# CKGEN_CM1 register map
Vendor: Texas Instruments
Peripheral module from a debugger description file (folder omap4460).
Registers are 32-bit, access per field, reset 0x0 unless marked. A register's access mark holds for its fields unless they carry their own. Offsets are as the file gives them; lines under a group give offsets from that group; [hi:lo] are bit positions; {n}, {i} and the like mark numbered series; 'fields as' and 'values as' point back to an identical list; <NAME> marks a mode.

## CKGEN_CM1
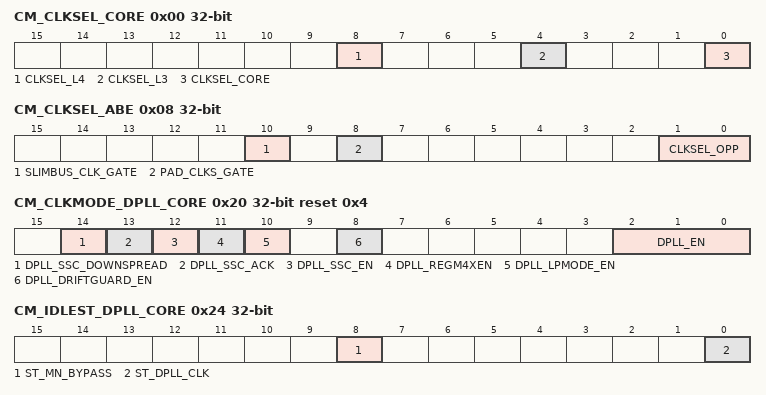
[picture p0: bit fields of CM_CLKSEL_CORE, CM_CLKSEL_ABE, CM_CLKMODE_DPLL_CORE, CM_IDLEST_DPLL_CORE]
0x00 CM_CLKSEL_CORE — CORE module clock selection.
  [8] CLKSEL_L4 rw — Selects L4 interconnect clock (L4_clk)
    0=L4_CLK is L3_CLK divided by 1; 1=L4_CLK is L3_CLK divided by 2, to be used for OPP100 and OPP50
  [4] CLKSEL_L3 rw — Selects L3 interconnect clock (L3_clk)
    0=L3_CLK is CORE_CLK divided by 1; 1=L3_CLK is CORE_CLK divided by 2, to be used for OPP100 and OPP50
  [0] CLKSEL_CORE rw — Selects CORE_CLK configuration
    0=CORE_CLK is CORE_X2_CLK divided by 1, to be used for OPP100 and OPP50; 1=CORE_CLK is CORE_X2_CLK divided by 2
0x08 CM_CLKSEL_ABE — ABE module clock selection.
  [10] SLIMBUS_CLK_GATE rw — Gating control for SLIMBUS_CLK clock tree in ABE. SLIMbus module always gets the ungated version.
    0=The clock is gated; 1=The clock is enabled
  [8] PAD_CLKS_GATE rw — Gating control for PAD_CLKS clock tree in ABE
    0=The clock is gated; 1=The clock is enabled
  [1:0] CLKSEL_OPP rw — Selects the OPP divider ABE domain
    0=ABE_CLK is divide by 1 of DPLL_ABE_X2_CLK, to be used for OPP100; 1=ABE_CLK is divide by 2 of DPLL_ABE_X2_CLK, to be used for OPP50; 2=ABE_CLK is divide by 4 of DPLL_ABE_X2_CLK
0x10 CM_DLL_CTRL reset 0x1 — Special register for DLL control
  [0] DLL_OVERRIDE rw — Control if DLL lock and code outputs are overriden or not
    0=Lock and code outputs are not overriden; 1=Lock output is overriden to 1 and code output is overriden with a value coming from control module
0x20 CM_CLKMODE_DPLL_CORE reset 0x4 — This register allows controlling the DPLL modes.
  [14] DPLL_SSC_DOWNSPREAD rw — Control if only low frequency spread is required
    0=When SSC is enabled, clock frequency is spread on both sides of the programmed frequency; 1=When SSC is enabled, clock frequency is spread only on the lower side of the programmed frequency
  [13] DPLL_SSC_ACK ro — Acknowledgement from the DPLL regarding start and stop of Spread Spectrum Clocking feature
    0=DPLL_SSC_ACK_0_r (SSC has been turned off on PLL o/ps); 1=DPLL_SSC_ACK_1_r (SSC has been turned on on PLL o/ps)
  [12] DPLL_SSC_EN rw — Enable or disable Spread Spectrum Clocking
    0=SSC disabled; 1=SSC enabled
  [11] DPLL_REGM4XEN ro — Enable the REGM4XEN mode of the DPLL. Please check the DPLL documentation to check when this mode can be enabled.
    0=DPLL_REGM4XEN_0_r (REGM4XEN mode of the DPLL is disabled)
  [10] DPLL_LPMODE_EN rw — Set the DPLL in low-power mode. Check the DPLL documentation to see when this can be enabled.
    0=Low-power mode of the DPLL is disabled; 1=Low-power mode of the DPLL is enabled
  [8] DPLL_DRIFTGUARD_EN rw — This bit allows to enable or disable the automatic recalibration feature of the DPLL. The DPLL will automatically start a recalibration process upon assertion of the DPLL's RECAL flag if this bit is set.
    0=DRIFTGUARD feature is disabled; 1=DRIFTGUARD feature is enabled
  [2:0] DPLL_EN rw — DPLL control. Upon Warm Reset, the PRCM DPLL control state machine updates this register to reflect MN bypass mode.
    4=Put the DPLL in MN bypass mode. The DPLL_MULT register bits are reset to 0 automatically by putting the DPLL in this mode.; 5=Put the DPLL in Idle bypass low-power mode; 6=Put the DPLL in Idle bypass fast-relock mode; 7=Enables the DPLL in lock mode
0x24 CM_IDLEST_DPLL_CORE ro — This register allows monitoring DPLL activity. This register is read only and automatically updated. [warm reset insensitive]
  [8] ST_MN_BYPASS — DPLL MN_BYPASS status
    1=ST_MN_BYPASS_1_r (DPLL is in MN_Bypass); 0=ST_MN_BYPASS_0_r (DPLL is not in MN_Bypass)
  [0] ST_DPLL_CLK — DPLL lock status
    1=ST_DPLL_CLK_1_r (DPLL is LOCKED); 0=ST_DPLL_CLK_0_r (DPLL is either in bypass mode or in stop mode.)
0x28 CM_AUTOIDLE_DPLL_CORE — This register provides automatic control over the DPLL activity.
  [2:0] AUTO_DPLL_MODE rw — DPLL automatic control.
    0=DPLL auto control disabled; 1=The DPLL is automatically put in low-power stop mode when its DPLL generated clocks are not required anymore. It is also restarted automatically.; 2=The DPLL is automatically put in fast-relock stop mode when its DPLL generated clocks are not required anymore. It is also restarted automatically.; 5=The DPLL is automatically put in idle bypass low-power mode when its DPLL generated clocks are not required anymore. It is also restarted automatically.; 6=The DPLL is automatically put in idle bypass fast-relock mode when its DPLL generated clocks are not required anymore. It is also restarted automatically.
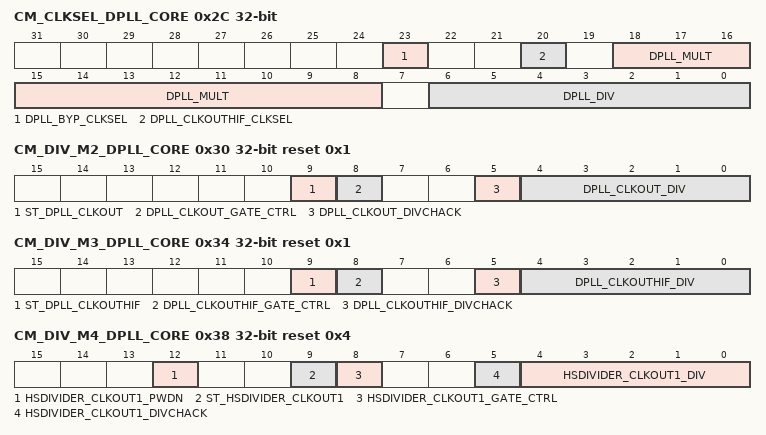
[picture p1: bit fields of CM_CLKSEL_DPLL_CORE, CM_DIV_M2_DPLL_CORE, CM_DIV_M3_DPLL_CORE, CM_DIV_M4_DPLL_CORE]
0x2C CM_CLKSEL_DPLL_CORE — This register provides controls over the DPLL.
  [23] DPLL_BYP_CLKSEL rw — Allows control of the BYPASS clock of the PLL and the associated HSDIVIDER. Same as ULOWCLKEN on DPLL. In DPLL locked mode, 0 - No impact 1 - No impact In DPLL bypass mode, 0 - CLKINP is selected as the BYPASS clock for CLKOUT/CLKOUTX2 1 - CLKINPULOW is selected as the BYPASS clock for CLKOUT/CLKOUTX2
  [20] DPLL_CLKOUTHIF_CLKSEL rw — Selects the source of the DPLL CLKOUTHIF clock. Same as CLKINPHIFSEL pin on the DPLL
    0=CLKOUTHIF is generated from the DPLL oscillator (DCO); 1=CLKOUTHIF is generated from CLKINPHIF
  [18:8] DPLL_MULT rw — DPLL multiplier factor (2 to 2047). This register is automatically cleared to 0 when the DPLL_EN field in the *CLKMODE_DPLL* register is set to select MN bypass mode. (equal to input M of DPLL; M=2 to 2047 = DPLL multiplies by M).
  [6:0] DPLL_DIV rw — DPLL divider factor (0 to 127) (equal to input N of DPLL; actual division factor is N+1).
0x30 CM_DIV_M2_DPLL_CORE reset 0x1 — This register provides controls over the M2 divider of the DPLL.
  [9] ST_DPLL_CLKOUT ro — DPLL CLKOUT status
    0=ST_DPLL_CLKOUT_0_r (The clock output is gated); 1=ST_DPLL_CLKOUT_1_r (The clock output is enabled)
  [8] DPLL_CLKOUT_GATE_CTRL rw — Control gating of DPLL CLKOUT
    0=Automatically gate this clock when there is no dependency for it; 1=Force this clock to stay enabled even if there is no request
  [5] DPLL_CLKOUT_DIVCHACK ro — Toggle on this status bit after changing DPLL_CLKOUT_DIV indicates that the change in divider value has taken effect
  [4:0] DPLL_CLKOUT_DIV rw — DPLL post-divider factor, M2, for internal clock generation (1 to 31); Divide value from 1 to 31.
    1=1, to be used for OPP100; 2=2, to be used for OPP50
0x34 CM_DIV_M3_DPLL_CORE reset 0x1 — This register provides controls over the M3 divider of the DPLL.
  [9] ST_DPLL_CLKOUTHIF ro — DPLL CLKOUTHIF status
    0=ST_DPLL_CLKOUTHIF_0_r (The clock output is gated); 1=ST_DPLL_CLKOUTHIF_1_r (The clock output is enabled)
  [8] DPLL_CLKOUTHIF_GATE_CTRL rw — Control gating of DPLL CLKOUTHIF
    0=Gate unconditionally this clock and stop requesting it; 1=Request this clock and un-gate it when available
  [5] DPLL_CLKOUTHIF_DIVCHACK ro — Toggle on this status bit after changing DPLL_CLKOUTHIF_DIV indicates that the change in divider value has taken effect
  [4:0] DPLL_CLKOUTHIF_DIV rw — DPLL post-divider factor, M3, for internal clock generation (1 to 31). Divide value from 1 to 31
    5=5, to be used for OPP100; 8=8, to be used for OPP50
0x38 CM_DIV_M4_DPLL_CORE reset 0x4 — This register provides controls over the CLKOUT1 o/p of the HSDIVIDER.
  [12] HSDIVIDER_CLKOUT1_PWDN rw — Direct power down control for HSDIVIDER M4 divider and CLKOUT1 output. Power down should be enabled only when clock is first gated.
    0=Divider is powered up; 1=Divider is powered down
  [9] ST_HSDIVIDER_CLKOUT1 ro — HSDIVIDER CLKOUT1 status
    0=ST_HSDIVIDER_CLKOUT1_0_r (The clock output is gated); 1=ST_HSDIVIDER_CLKOUT1_1_r (The clock output is enabled)
  [8] HSDIVIDER_CLKOUT1_GATE_CTRL rw — Control gating of HSDIVIDER CLKOUT1
    values as CM_DIV_M2_DPLL_CORE.DPLL_CLKOUT_GATE_CTRL
  [5] HSDIVIDER_CLKOUT1_DIVCHACK ro — Toggle on this status bit after changing HSDIVIDER_CLKOUT1_DIV indicates that the change in divider value has taken effect
  [4:0] HSDIVIDER_CLKOUT1_DIV rw — DPLL M4 post-divider factor (1 to 31).
    8=8, to be used for OPP100 and OPP50
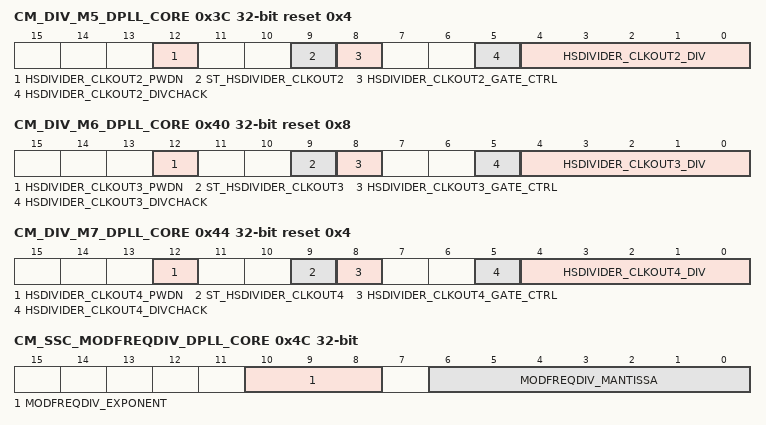
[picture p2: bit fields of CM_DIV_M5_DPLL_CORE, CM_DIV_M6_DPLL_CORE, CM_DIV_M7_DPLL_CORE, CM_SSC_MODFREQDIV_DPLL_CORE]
0x3C CM_DIV_M5_DPLL_CORE reset 0x4 — This register provides controls over the CLKOUT2 o/p of the HSDIVIDER.
  [12] HSDIVIDER_CLKOUT2_PWDN rw — Direct power down control for HSDIVIDER M5 divider and CLKOUT2 output. Power down should be enabled only when clock is first gated.
    0=Divider is powered up; 1=Divider is powered down
  [9] ST_HSDIVIDER_CLKOUT2 ro — HSDIVIDER CLKOUT2 status
    0=ST_HSDIVIDER_CLKOUT2_0_r (The clock output is gated); 1=ST_HSDIVIDER_CLKOUT2_1_r (The clock output is enabled)
  [8] HSDIVIDER_CLKOUT2_GATE_CTRL rw — Control gating of HSDIVIDER CLKOUT2
    values as CM_DIV_M2_DPLL_CORE.DPLL_CLKOUT_GATE_CTRL
  [5] HSDIVIDER_CLKOUT2_DIVCHACK ro — Toggle on this status bit after changing HSDIVIDER_CLKOUT2_DIV indicates that the change in divider value has taken effect
  [4:0] HSDIVIDER_CLKOUT2_DIV rw — DPLL M5 post-divider factor (1 to 31)
    4=4, to be used for OPP100; 8=8, to be used for OPP50
0x40 CM_DIV_M6_DPLL_CORE reset 0x8 — This register provides controls over the CLKOUT3 o/p of the HSDIVIDER.
  [12] HSDIVIDER_CLKOUT3_PWDN rw — Direct power down control for HSDIVIDER M6 divider and CLKOUT3 output. Power down should be enabled only when clock is first gated.
    0=Divider is powered up; 1=Divider is powered down
  [9] ST_HSDIVIDER_CLKOUT3 ro — HSDIVIDER CLKOUT3 status
    0=ST_HSDIVIDER_CLKOUT3_0_r (The clock output is gated); 1=ST_HSDIVIDER_CLKOUT3_1_r (The clock output is enabled)
  [8] HSDIVIDER_CLKOUT3_GATE_CTRL rw — Control gating of HSDIVIDER CLKOUT3
    values as CM_DIV_M2_DPLL_CORE.DPLL_CLKOUT_GATE_CTRL
  [5] HSDIVIDER_CLKOUT3_DIVCHACK ro — Toggle on this status bit after changing HSDIVIDER_CLKOUT3_DIV indicates that the change in divider value has taken effect
  [4:0] HSDIVIDER_CLKOUT3_DIV rw — DPLL M6 post-divider factor (1 to 31)
    6=6, to be used for OPP100; 8=8, to be used for OPP50
0x44 CM_DIV_M7_DPLL_CORE reset 0x4 — This register provides controls over the CLKOUT4 o/p of the HSDIVIDER.
  [12] HSDIVIDER_CLKOUT4_PWDN rw — Direct power down control for HSDIVIDER M7 divider and CLKOUT4 output. Power down should be enabled only when clock is first gated.
    0=Divider is powered up; 1=Divider is powered down
  [9] ST_HSDIVIDER_CLKOUT4 ro — HSDIVIDER CLKOUT4 status
    0=ST_HSDIVIDER_CLKOUT4_0_r (The clock output is gated); 1=ST_HSDIVIDER_CLKOUT4_1_r (The clock output is enabled)
  [8] HSDIVIDER_CLKOUT4_GATE_CTRL rw — Control gating of HSDIVIDER CLKOUT4
    values as CM_DIV_M2_DPLL_CORE.DPLL_CLKOUT_GATE_CTRL
  [5] HSDIVIDER_CLKOUT4_DIVCHACK ro — Toggle on this status bit after changing HSDIVIDER_CLKOUT4_DIV indicates that the change in divider value has taken effect
  [4:0] HSDIVIDER_CLKOUT4_DIV rw — DPLL M7 post-divider factor (1 to 31)
    6=6, to be used for OPP100 for 266.7-MHz clock output; 8=8, to be used for OPP100 for 200-MHz clock output; 12=12, to be used for OPP50 for 133.3-MHz clock output; 16=16, to be used for OPP50 for 100-MHz clock output
0x48 CM_SSC_DELTAMSTEP_DPLL_CORE — Control the DeltaMStep parameter for Spread Spectrum Clocking. [warm reset insensitive]
  [19:0] DELTAMSTEP rw — DeltaMStep is split into fractional and integer part. For Triangular Spread Spectrum: [19:18] for integer part, [17:0] for fractional part For Square Wave Spread Spectrum [19:14] for integer part, [13:0] for fractional part
0x4C CM_SSC_MODFREQDIV_DPLL_CORE — Control the Modulation Frequency (Fm) for Spread Spectrum. [warm reset insensitive]
  [10:8] MODFREQDIV_EXPONENT rw — Set the Exponent component of MODFREQDIV factor
  [6:0] MODFREQDIV_MANTISSA rw — Set the Mantissa component of MODFREQDIV factor
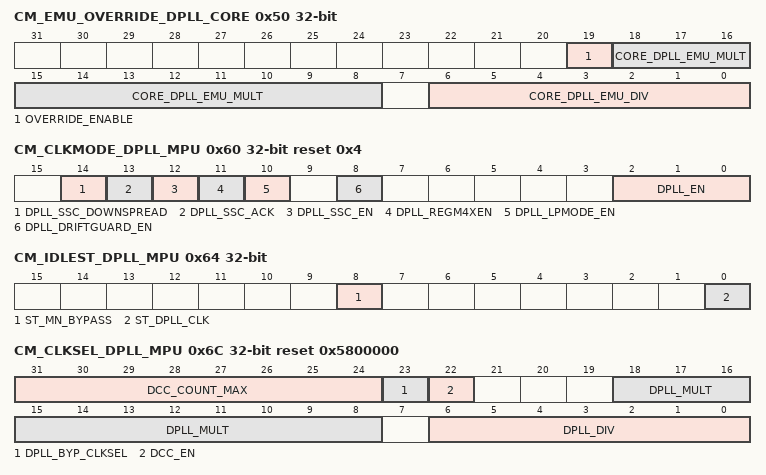
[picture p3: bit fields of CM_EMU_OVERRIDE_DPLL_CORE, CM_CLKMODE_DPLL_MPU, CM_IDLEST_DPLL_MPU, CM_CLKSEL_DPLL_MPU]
0x50 CM_EMU_OVERRIDE_DPLL_CORE — This register provides emulation override controls over the CORE DPLL.
  [19] OVERRIDE_ENABLE rw — This bit allows to enable or disable the emulation override controls
    0=The emulation override controls are disabled; 1=The emulation override controls are enabled
  [18:8] CORE_DPLL_EMU_MULT rw — DPLL multiplier factor (2 to 2047). (equal to input M of DPLL; M=2 to 2047 = DPLL multiplies by M)
  [6:0] CORE_DPLL_EMU_DIV rw — CORE DPLL override divider factor (0 to 127) (equal to input N of DPLL; actual division factor is N+1).
0x60 CM_CLKMODE_DPLL_MPU reset 0x4 — This register allows controlling the DPLL modes.
  [14] DPLL_SSC_DOWNSPREAD rw — Control if only low frequency spread is required
    values as CM_CLKMODE_DPLL_CORE.DPLL_SSC_DOWNSPREAD
  [13] DPLL_SSC_ACK ro — Acknowledgement from the DPLL regarding start and stop of Spread Spectrum Clocking feature
    values as CM_CLKMODE_DPLL_CORE.DPLL_SSC_ACK
  [12] DPLL_SSC_EN rw — Enable or disable Spread Spectrum Clocking
    0=SSC disabled; 1=SSC enabled
  [11] DPLL_REGM4XEN ro — Enable the REGM4XEN mode of the DPLL. Please check the DPLL documentation to check when this mode can be enabled.
    0=DPLL_REGM4XEN_0_r (REGM4XEN mode of the DPLL is disabled)
  [10] DPLL_LPMODE_EN rw — Set the DPLL in low-power mode. Check the DPLL documentation to see when this can be enabled.
    values as CM_CLKMODE_DPLL_CORE.DPLL_LPMODE_EN
  [8] DPLL_DRIFTGUARD_EN rw — This bit allows to enable or disable the automatic recalibration feature of the DPLL. The DPLL will automatically start a recalibration process upon assertion of the DPLL's RECAL flag if this bit is set.
    values as CM_CLKMODE_DPLL_CORE.DPLL_DRIFTGUARD_EN
  [2:0] DPLL_EN rw — DPLL control. Upon Warm Reset, the PRCM DPLL control state machine updates this register to reflect MN bypass mode.
    4=Put the DPLL in MN bypass mode. The DPLL_MULT register bits are reset to 0 automatically by putting the DPLL in this mode.; 5=Put the DPLL in idle bypass low-power mode; 6=Put the DPLL in idle bypass fast-relock mode; 7=Enables the DPLL in lock mode
0x64 CM_IDLEST_DPLL_MPU ro — This register allows monitoring DPLL activity. This register is read only and automatically updated. [warm reset insensitive]
  fields as CM_IDLEST_DPLL_CORE
0x68 CM_AUTOIDLE_DPLL_MPU — This register provides automatic control over the DPLL activity.
  [2:0] AUTO_DPLL_MODE rw — DPLL automatic control;
    values as CM_AUTOIDLE_DPLL_CORE.AUTO_DPLL_MODE
0x6C CM_CLKSEL_DPLL_MPU access not given reset 0x5800000 — This register provides controls over the DPLL.
  [31:24] DCC_COUNT_MAX rw — The value 'NbCycles' set in this field determines the duration of the clock ramp step during which the output frequency is Fdpll/(2*M2). The duration is computed as 32 x NbCycles of L4 clock cycles (100 MHz). Duration should be 2.5 µs to allow enough time for DCC to lock. This bit field is relevant only when DCC_EN = 1.
  [23] DPLL_BYP_CLKSEL — Only CLKINPULOW bypass clock supported for this PLL (access R Returns 1s)
  [22] DCC_EN rw — Enable or disable duty cycle correction. Must be enabled only for frequency 1 GHz.When enabled, the CLKOUTHIF output of the DPLL is used after duty cycle correction instead of CLKOUT. The M3 divider is hard-wired to 1 so the lock frequency Fdpll is directly provided to MPU. .
    0=DCC disabled; 1=DCC enabled
  [18:8] DPLL_MULT rw — DPLL multiplier factor (2 to 2047). This register is automatically cleared to 0 when the DPLL_EN field in the *CLKMODE_DPLL* register is set to select MN bypass mode. (equal to input M of DPLL; M=2 to 2047 = DPLL multiplies by M).
  [6:0] DPLL_DIV rw — DPLL divider factor (0 to 127) (equal to input N of DPLL; actual division factor is N+1).
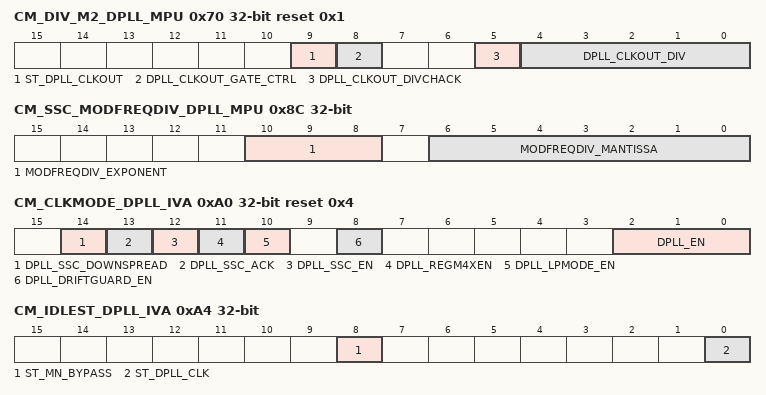
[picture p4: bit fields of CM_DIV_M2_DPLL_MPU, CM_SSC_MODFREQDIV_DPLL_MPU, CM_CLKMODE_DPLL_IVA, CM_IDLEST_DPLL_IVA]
0x70 CM_DIV_M2_DPLL_MPU reset 0x1 — This register provides controls over the M2 divider of the DPLL.
  [9] ST_DPLL_CLKOUT ro — DPLL CLKOUT status
    values as CM_DIV_M2_DPLL_CORE.ST_DPLL_CLKOUT
  [8] DPLL_CLKOUT_GATE_CTRL rw — Control gating of DPLL CLKOUT
    values as CM_DIV_M2_DPLL_CORE.DPLL_CLKOUT_GATE_CTRL
  [5] DPLL_CLKOUT_DIVCHACK ro — Toggle on this status bit after changing DPLL_CLKOUT_DIV indicates that the change in divider value has taken effect
  [4:0] DPLL_CLKOUT_DIV rw — DPLL post-divider factor, M2, for internal clock generation (1 to 31);Divide value from 1 to 31
    1=1, to be used for OPP100, OPP_TURBO, OPP_NITRO, and OPP_NITROSB; 2=2, to be used for OPP50
0x88 CM_SSC_DELTAMSTEP_DPLL_MPU — Control the DeltaMStep parameter for Spread Spectrum Clocking. [warm reset insensitive]
  fields as CM_SSC_DELTAMSTEP_DPLL_CORE
0x8C CM_SSC_MODFREQDIV_DPLL_MPU — Control the Modulation Frequency (Fm) for Spread Spectrum. [warm reset insensitive]
  fields as CM_SSC_MODFREQDIV_DPLL_CORE
0x9C CM_BYPCLK_DPLL_MPU — Control MPU PLL BYPASS clock. [warm reset insensitive]
  [1:0] CLKSEL rw — Select the DPLL MPU bypass clock
    0=DPLL_MPU bypass clock is CORE_X2_CLK divided by 1, to be used for OPP100 and OPP50; 1=DPLL_MPU bypass clock is CORE_X2_CLK divided by 2; 2=DPLL_MPU bypass clock is CORE_X2_CLK divided by 4; 3=DPLL_MPU bypass clock is CORE_X2_CLK divided by 8
0xA0 CM_CLKMODE_DPLL_IVA reset 0x4 — This register allows controlling the DPLL modes.
  [14] DPLL_SSC_DOWNSPREAD rw — Control if only low frequency spread is required
    values as CM_CLKMODE_DPLL_CORE.DPLL_SSC_DOWNSPREAD
  [13] DPLL_SSC_ACK ro — Acknowledgement from the DPLL regarding start and stop of Spread Spectrum Clocking feature
    values as CM_CLKMODE_DPLL_CORE.DPLL_SSC_ACK
  [12] DPLL_SSC_EN rw — Enable or disable Spread Spectrum Clocking
    0=SSC disabled; 1=SSC enabled
  [11] DPLL_REGM4XEN ro — Enable the REGM4XEN mode of the DPLL. Please check the DPLL documentation to check when this mode can be enabled.
    0=DPLL_REGM4XEN_0_r (REGM4XEN mode of the DPLL is disabled)
  [10] DPLL_LPMODE_EN rw — Set the DPLL in low-power mode. Check the DPLL documentation to see when this can be enabled.
    values as CM_CLKMODE_DPLL_CORE.DPLL_LPMODE_EN
  [8] DPLL_DRIFTGUARD_EN rw — This bit allows to enable or disable the automatic recalibration feature of the DPLL. The DPLL will automatically start a recalibration process upon assertion of the DPLL's RECAL flag if this bit is set.
    values as CM_CLKMODE_DPLL_CORE.DPLL_DRIFTGUARD_EN
  [2:0] DPLL_EN rw — DPLL control. Upon Warm Reset, the PRCM DPLL control state machine updates this register to reflect MN bypass mode.
    4=Put the DPLL in MN bypass mode. The DPLL_MULT register bits are reset to 0 automatically by putting the DPLL in this mode.; 5=Put the DPLL in idle bypass low-power mode; 7=Enables the DPLL in lock mode
0xA4 CM_IDLEST_DPLL_IVA ro — This register allows monitoring DPLL activity. This register is read only and automatically updated. [warm reset insensitive]
  fields as CM_IDLEST_DPLL_CORE
0xA8 CM_AUTOIDLE_DPLL_IVA — This register provides automatic control over the DPLL activity.
  [2:0] AUTO_DPLL_MODE rw — DPLL automatic control;
    0=DPLL auto control disabled; 1=The DPLL is automatically put in low-power stop mode when its DPLL generated clocks are not required anymore. It is also restarted automatically.; 2=The DPLL is automatically put in fast-relock stop mode when its DPLL generated clocks are not required anymore. It is also restarted automatically.; 5=The DPLL is automatically put in idle bypass low-power mode when its DPLL generated clocks are not required anymore. It is also restarted automatically.
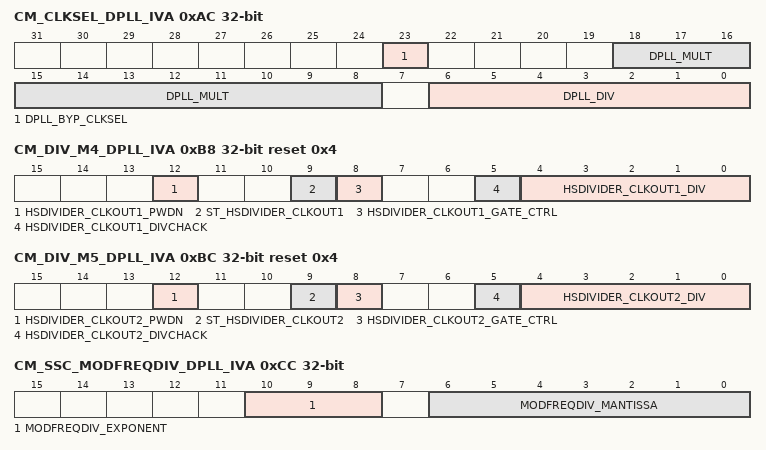
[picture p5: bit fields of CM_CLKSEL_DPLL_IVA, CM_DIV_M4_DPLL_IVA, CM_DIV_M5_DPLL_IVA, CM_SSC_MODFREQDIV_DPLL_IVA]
0xAC CM_CLKSEL_DPLL_IVA — This register provides controls over the DPLL.
  [23] DPLL_BYP_CLKSEL rw — Allows control of the BYPASS clock of the PLL and the associated HSDIVIDER. Same as ULOWCLKEN on DPLL. In DPLL locked mode, 0 - No impact 1 - No impact In DPLL bypass mode, 0 - CLKINP is selected as the BYPASS clock for CLKOUT/CLKOUTX2 1 - CLKINPULOW is selected as the BYPASS clock for CLKOUT/CLKOUTX2
  [18:8] DPLL_MULT rw — DPLL multiplier factor (2 to 2047). This register is automatically cleared to 0 when the DPLL_EN field in the *CLKMODE_DPLL* register is set to select MN bypass mode. (equal to input M of DPLL; M=2 to 2047 = DPLL multiplies by M).
  [6:0] DPLL_DIV rw — DPLL divider factor (0 to 127) (equal to input N of DPLL; actual division factor is N+1).
0xB8 CM_DIV_M4_DPLL_IVA reset 0x4 — This register provides controls over the CLKOUT1 o/p of the HSDIVIDER.
  [12] HSDIVIDER_CLKOUT1_PWDN rw — Direct power down control for HSDIVIDER M4 divider and CLKOUT1 output. Power down should be enabled only when clock is first gated.
    0=Divider is powered up; 1=Divider is powered down
  [9] ST_HSDIVIDER_CLKOUT1 ro — HSDIVIDER CLKOUT1 status
    values as CM_DIV_M4_DPLL_CORE.ST_HSDIVIDER_CLKOUT1
  [8] HSDIVIDER_CLKOUT1_GATE_CTRL rw — Control gating of HSDIVIDER CLKOUT1
    values as CM_DIV_M2_DPLL_CORE.DPLL_CLKOUT_GATE_CTRL
  [5] HSDIVIDER_CLKOUT1_DIVCHACK ro — Toggle on this status bit after changing HSDIVIDER_CLKOUT1_DIV indicates that the change in divider value has taken effect
  [4:0] HSDIVIDER_CLKOUT1_DIV rw — DPLL M4 post-divider factor (1 to 31)
    2=2, to be used for OPP_TURBO and OPP_NITRO; 4=4, to be used for OPP100; 8=8, to be used for OPP50
0xBC CM_DIV_M5_DPLL_IVA reset 0x4 — This register provides controls over the CLKOUT2 o/p of the HSDIVIDER.
  [12] HSDIVIDER_CLKOUT2_PWDN rw — Direct power down control for HSDIVIDER M5 divider and CLKOUT2 output. Power down should be enabled only when clock is first gated.
    0=Divider is powered up; 1=Divider is powered down
  [9] ST_HSDIVIDER_CLKOUT2 ro — HSDIVIDER CLKOUT2 status
    values as CM_DIV_M5_DPLL_CORE.ST_HSDIVIDER_CLKOUT2
  [8] HSDIVIDER_CLKOUT2_GATE_CTRL rw — Control gating of HSDIVIDER CLKOUT2
    values as CM_DIV_M2_DPLL_CORE.DPLL_CLKOUT_GATE_CTRL
  [5] HSDIVIDER_CLKOUT2_DIVCHACK ro — Toggle on this status bit after changing HSDIVIDER_CLKOUT2_DIV indicates that the change in divider value has taken effect.
  [4:0] HSDIVIDER_CLKOUT2_DIV rw — DPLL M5 post-divider factor (1 to 31)
    2=2, to be used for OPP_NITRO; 3=3, to be used for OPP_TURBO; 7=7, to be used for OPP100; 14=14, to be used for OPP50
0xC8 CM_SSC_DELTAMSTEP_DPLL_IVA — Control the DeltaMStep parameter for Spread Spectrum Clocking. [warm reset insensitive]
  fields as CM_SSC_DELTAMSTEP_DPLL_CORE
0xCC CM_SSC_MODFREQDIV_DPLL_IVA — Control the Modulation Frequency (Fm) for Spread Spectrum. [warm reset insensitive]
  fields as CM_SSC_MODFREQDIV_DPLL_CORE
0xDC CM_BYPCLK_DPLL_IVA — Control IVA PLL BYPASS clock. [warm reset insensitive]
  [1:0] CLKSEL rw — Select the DPLL IVA bypass clock
    0=DPLL_IVA bypass clock is CORE_X2_CLK divided by 1, to be used for OPP100 and OPP50; 1=DPLL_IVA bypass clock is CORE_X2_CLK divided by 2; 2=DPLL_IVA bypass clock is CORE_X2_CLK divided by 4; 3=DPLL_IVA bypass clock is CORE_X2_CLK divided by 8
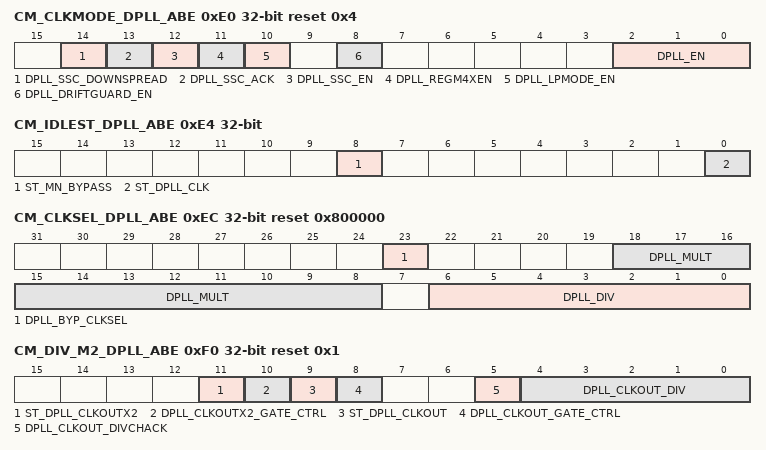
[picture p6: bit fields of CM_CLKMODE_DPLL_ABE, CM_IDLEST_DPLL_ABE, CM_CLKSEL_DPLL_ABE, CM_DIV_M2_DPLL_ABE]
0xE0 CM_CLKMODE_DPLL_ABE reset 0x4 — This register allows controlling the DPLL modes.
  [14] DPLL_SSC_DOWNSPREAD rw — Control if only low frequency spread is required
    values as CM_CLKMODE_DPLL_CORE.DPLL_SSC_DOWNSPREAD
  [13] DPLL_SSC_ACK ro — Acknowledgement from the DPLL regarding start and stop of Spread Spectrum Clocking feature
    values as CM_CLKMODE_DPLL_CORE.DPLL_SSC_ACK
  [12] DPLL_SSC_EN rw — Enable or disable Spread Spectrum Clocking
    0=SSC disabled; 1=SSC enabled
  [11] DPLL_REGM4XEN rw — Enable the REGM4XEN mode of the DPLL. Please check the DPLL documentation to check when this mode can be enabled.
    0=DPLL_REGM4XEN_0_r (REGM4XEN mode of the DPLL is disabled)
  [10] DPLL_LPMODE_EN rw — Set the DPLL in low-power mode. Check the DPLL documentation to see when this can be enabled.
    values as CM_CLKMODE_DPLL_CORE.DPLL_LPMODE_EN
  [8] DPLL_DRIFTGUARD_EN rw — This bit allows to enable or disable the automatic recalibration feature of the DPLL. The DPLL will automatically start a recalibration process upon assertion of the DPLL's RECAL flag if this bit is set.
    values as CM_CLKMODE_DPLL_CORE.DPLL_DRIFTGUARD_EN
  [2:0] DPLL_EN rw — DPLL control. Upon Warm Reset, the PRCM DPLL control state machine updates this register to reflect MN bypass mode.
    values as CM_CLKMODE_DPLL_MPU.DPLL_EN
0xE4 CM_IDLEST_DPLL_ABE ro — This register allows monitoring DPLL activity. This register is read only and automatically updated. [warm reset insensitive]
  fields as CM_IDLEST_DPLL_CORE
0xE8 CM_AUTOIDLE_DPLL_ABE — This register provides automatic control over the DPLL activity.
  fields as CM_AUTOIDLE_DPLL_MPU
0xEC CM_CLKSEL_DPLL_ABE access not given reset 0x800000 — This register provides controls over the DPLL.
  [23] DPLL_BYP_CLKSEL — Only CLKINPULOW bypass clock supported for this PLL (access R Rreturns1s)
  [18:8] DPLL_MULT rw — DPLL multiplier factor (2 to 2047). This register is automatically cleared to 0 when the DPLL_EN field in the *CLKMODE_DPLL* register is set to select MN bypass mode. (equal to input M of DPLL; M=2 to 2047 = DPLL multiplies by M).
  [6:0] DPLL_DIV rw — DPLL divider factor (0 to 127) (equal to input N of DPLL; actual division factor is N+1).
0xF0 CM_DIV_M2_DPLL_ABE reset 0x1 — This register provides controls over the M2 divider of the DPLL.
  [11] ST_DPLL_CLKOUTX2 ro — DPLL CLKOUTX2 status
    0=ST_DPLL_CLKOUTX2_0_r (The clock output is gated); 1=ST_DPLL_CLKOUTX2_1_r (The clock output is enabled)
  [10] DPLL_CLKOUTX2_GATE_CTRL rw — Control gating of DPLL CLKOUTX2
    values as CM_DIV_M2_DPLL_CORE.DPLL_CLKOUT_GATE_CTRL
  [9] ST_DPLL_CLKOUT ro — DPLL CLKOUT status
    values as CM_DIV_M2_DPLL_CORE.ST_DPLL_CLKOUT
  [8] DPLL_CLKOUT_GATE_CTRL rw — Control gating of DPLL CLKOUT
    values as CM_DIV_M2_DPLL_CORE.DPLL_CLKOUT_GATE_CTRL
  [5] DPLL_CLKOUT_DIVCHACK ro — Toggle on this status bit after changing DPLL_CLKOUT_DIV indicates that the change in divider value has taken effect.
  [4:0] DPLL_CLKOUT_DIV rw — DPLL post-divider factor, M2, for internal clock generation (1 to 31). Divide value from 1 to 31
    1=1, to be used for OPP100 and OPP50
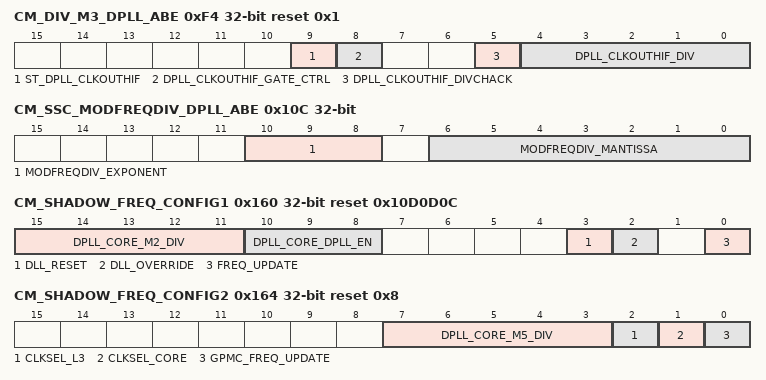
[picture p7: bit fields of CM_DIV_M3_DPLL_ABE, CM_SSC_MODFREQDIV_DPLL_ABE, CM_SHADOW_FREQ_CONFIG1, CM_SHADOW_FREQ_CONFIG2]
0xF4 CM_DIV_M3_DPLL_ABE reset 0x1 — This register provides controls over the M3 divider of the DPLL.
  [9] ST_DPLL_CLKOUTHIF ro — DPLL CLKOUTHIF status
    values as CM_DIV_M3_DPLL_CORE.ST_DPLL_CLKOUTHIF
  [8] DPLL_CLKOUTHIF_GATE_CTRL rw — Control gating of DPLL CLKOUTHIF
    values as CM_DIV_M2_DPLL_CORE.DPLL_CLKOUT_GATE_CTRL
  [5] DPLL_CLKOUTHIF_DIVCHACK ro — Toggle on this status bit after changing DPLL_CLKOUTHIF_DIV indicates that the change in divider value has taken effect.
  [4:0] DPLL_CLKOUTHIF_DIV rw — DPLL post-divider factor, M3, for internal clock generation (1 to 31). Divide value from 1 to 31
    1=1, to be used for OPP100 and OPP50
0x108 CM_SSC_DELTAMSTEP_DPLL_ABE — Control the DeltaMStep parameter for Spread Spectrum Clocking. [warm reset insensitive]
  fields as CM_SSC_DELTAMSTEP_DPLL_CORE
0x10C CM_SSC_MODFREQDIV_DPLL_ABE — Control the Modulation Frequency (Fm) for Spread Spectrum. [warm reset insensitive]
  fields as CM_SSC_MODFREQDIV_DPLL_CORE
0x160 CM_SHADOW_FREQ_CONFIG1 access not given reset 0x10D0D0C — Shadow register to program new DPLL configuration affecting EMIF and GPMC (L3 clock) functional frequency during DVFS. The PRCM h/w automatically applies the new configuration after EMIF/GPMC have been put in idle state.
  [15:11] DPLL_CORE_M2_DIV rw — Shadow register forCM_DIV_M2_DPLL_CORE.DPLL_CLKOUT_DIV. The main register is automatically loaded with the shadow register value after EMIF IDLE if the FREQ_UPDATE field is set to 1. Divide value from 1 to 31.
  [10:8] DPLL_CORE_DPLL_EN rw — Shadow register forCM_CLKMODE_DPLL_CORE.DPLL_EN. The main register is automatically loaded with the shadow register value after EMIF IDLE if the FREQ_UPDATE field is set to 1.
    values as CM_CLKMODE_DPLL_MPU.DPLL_EN
  [3] DLL_RESET rw — Specify if DLL should be reset or not during the frequency change hardware sequence.
    0=DLL is not reset during the frequency change hardware sequence; 1=DLL is reset automatically during the frequency change hardware sequence
  [2] DLL_OVERRIDE rw — Shadow register forCM_DLL_CTRL.DLL_OVERRIDE.The main register is automatically loaded with the shadow register value after EMIF IDLE if the FREQ_UPDATE field is set to 1.
    values as CM_DLL_CTRL.DLL_OVERRIDE
  [0] FREQ_UPDATE — Writing 1 indicates that a new configuration is available. It is automatically cleared by h/w after the configuration has been applied. (access RW WSpecial)
0x164 CM_SHADOW_FREQ_CONFIG2 reset 0x8 — Shadow register to program new DPLL configuration affecting GPMC (L3 clock) functional frequency during DVFS. The PRCM h/w automatically applies the new configuration after EMIF/GPMC have been put in idle state.
  [7:3] DPLL_CORE_M5_DIV rw — Shadow register forCM_DIV_M5_DPLL_CORE.HSDIVIDER_CLKOUT2_DIV. The main register is automatically loaded with the shadow register value after GPMC IDLE if the CM_SHADOW_FREQ_CONFIG1.FREQ_UPDATE field is set to 1 and GPMC_FREQ_UPDATE is set to 1. Divide value from 1 to 31.
  [2] CLKSEL_L3 rw — Shadow register forCM_CLKSEL_CORE.CLKSEL_L3. The main register is automatically loaded with the shadow register value after GPMC IDLE if the CM_SHADOW_FREQ_CONFIG1.FREQ_UPDATE field is set to 1 and GPMC_FREQ_UPDATE is set to 1.
    0=L3_CLK is CORE_CLK divided by 1; 1=L3_CLK is CORE_CLK divided by 2
  [1] CLKSEL_CORE rw — Shadow register forCM_CLKSEL_CORE.CLKSEL_CORE. The main register is automatically loaded with the shadow register value after GPMC IDLE if the CM_SHADOW_FREQ_CONFIG1.FREQ_UPDATE field is set to 1 and GPMC_FREQ_UPDATE is set to 1.
    0=CORE_CLK is CORE_X2_CLK divided by 1; 1=CORE_CLK is CORE_X2_CLK divided by 2
  [0] GPMC_FREQ_UPDATE rw — Controls whether or not GPMC has to be put automatically into idle during the frequency change operation.
    0=GPMC is not put automatically into idle during frequency change operation; 1=GPMC is put automatically into idle during frequency change operation
0x170 CM_DYN_DEP_PRESCAL reset 0x20 — Control the time unit of the sliding window for dynamic dependencies (auto-sleep feature).
  [5:0] PRESCAL rw — Time unit is equal to (PRESCAL + 1) L4 clock cycles.
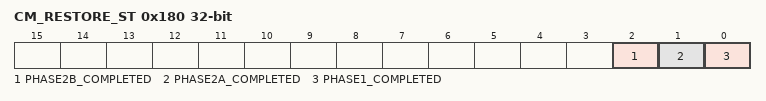
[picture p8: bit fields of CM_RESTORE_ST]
0x180 CM_RESTORE_ST — Automatic restore status. This register is used by the system DMA to write a predefined value at the end of end automatic restore phase. [warm reset insensitive]
  [2] PHASE2B_COMPLETED rw — Indicates if restore phase 2b is completed. Must be cleared by software before going to device OFF mode.
  [1] PHASE2A_COMPLETED rw — Indicates if restore phase 2a is completed. Must be cleared by software before going to device OFF mode.
  [0] PHASE1_COMPLETED rw — Indicates if restore phase 1 is completed. Must be cleared by software before going to device OFF mode.
